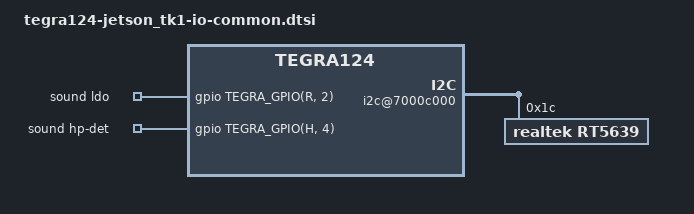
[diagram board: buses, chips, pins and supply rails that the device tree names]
/*
 * tegra124-jetson_tk1-io-common.dtsi: Common IO file for Jetson TK1
 *
 * Copyright (c) 2016, NVIDIA CORPORATION.  All rights reserved.
 *
 * This program is free software; you can redistribute it and/or modify
 * it under the terms of the GNU General Public License as published by
 * the Free Software Foundation; either version 2 of the License, or
 * (at your option) any later version.
 *
 * This program is distributed in the hope that it will be useful, but WITHOUT
 * ANY WARRANTY; without even the implied warranty of MERCHANTABILITY or
 * FITNESS FOR A PARTICULAR PURPOSE.  See the GNU General Public License for
 * more details.
 */

/* This file is mainly for IO-Peripherals like SPI/I2C/USB/UART etc */

/ {
	i2c@7000c000 {
		rt5639: rt5639.0-001c@1c {
			compatible = "realtek,rt5639";
			reg = <0x1c>;
		};
	};

	sound {
		compatible = "nvidia,tegra-audio-rt5639";
		nvidia,codec_name = "rt5639.0-001a";
		nvidia,codec_dai_name = "rt5639-aif1";
		nvidia,ldo-gpios = <&gpio TEGRA_GPIO(R, 2) 0>;
		nvidia,hp-det-gpios = <&gpio TEGRA_GPIO(H, 4) 0>;
		nvidia,use_codec_jd_irq = <1>;
		nvidia,i2s-param-hifi = <1 1 2 16 48000 2 1536000>;
		nvidia,i2s-param-bt = <3 1 0 16 8000 1 512000>;
		nvidia,i2s-param-baseband = <0 1 2 16 16000 2 1024000>;
	};
};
